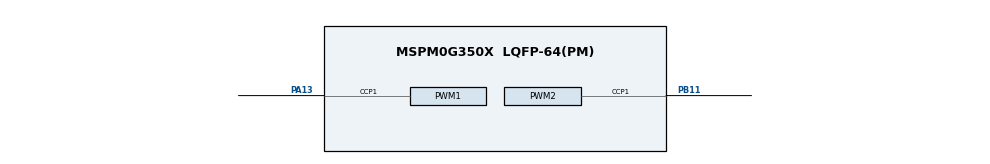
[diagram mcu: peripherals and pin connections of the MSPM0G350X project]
/**
 * @cliArgs --device "MSPM0G350X" --part "Default" --package "LQFP-64(PM)" --product "mspm0_sdk@2.05.00.05"
 * @versions {"tool":"1.24.0+4110"}
 */

/**
 * Import the modules used in this configuration.
 */
const GPIO   = scripting.addModule("/ti/driverlib/GPIO", {}, false);
const GPIO1  = GPIO.addInstance();
const GPIO2  = GPIO.addInstance();
const GPIO3  = GPIO.addInstance();
const GPIO4  = GPIO.addInstance();
const PWM    = scripting.addModule("/ti/driverlib/PWM", {}, false);
const PWM1   = PWM.addInstance();
const PWM2   = PWM.addInstance();
const SYSCTL = scripting.addModule("/ti/driverlib/SYSCTL");

/**
 * Write custom configuration values to the imported modules.
 */
GPIO1.$name                          = "GPIO_LEFT_MOTOR";
GPIO1.associatedPins.create(2);
GPIO1.associatedPins[0].$name        = "LEFT_PIN_0";
GPIO1.associatedPins[0].assignedPort = "PORTA";
GPIO1.associatedPins[0].assignedPin  = "28";
GPIO1.associatedPins[0].initialValue = "SET";
GPIO1.associatedPins[1].$name        = "LEFT_PIN_1";
GPIO1.associatedPins[1].initialValue = "SET";
GPIO1.associatedPins[1].assignedPort = "PORTA";
GPIO1.associatedPins[1].assignedPin  = "31";

const Board = scripting.addModule("/ti/driverlib/Board", {}, false);

GPIO2.$name                          = "GPIO_RIGHT_MOTOR";
GPIO2.associatedPins.create(2);
GPIO2.associatedPins[0].$name        = "RIGHT_PIN_0";
GPIO2.associatedPins[0].initialValue = "SET";
GPIO2.associatedPins[0].assignedPort = "PORTB";
GPIO2.associatedPins[0].assignedPin  = "13";
GPIO2.associatedPins[1].$name        = "RIGHT_PIN_1";
GPIO2.associatedPins[1].initialValue = "SET";
GPIO2.associatedPins[1].assignedPort = "PORTB";
GPIO2.associatedPins[1].assignedPin  = "20";

GPIO3.$name                          = "GPIO_SENSOR";
GPIO3.associatedPins.create(8);
GPIO3.associatedPins[0].$name        = "PIN_0";
GPIO3.associatedPins[0].direction    = "INPUT";
GPIO3.associatedPins[0].assignedPort = "PORTB";
GPIO3.associatedPins[0].assignedPin  = "3";
GPIO3.associatedPins[1].$name        = "PIN_1";
GPIO3.associatedPins[1].direction    = "INPUT";
GPIO3.associatedPins[1].assignedPort = "PORTB";
GPIO3.associatedPins[1].assignedPin  = "2";
GPIO3.associatedPins[2].$name        = "PIN_2";
GPIO3.associatedPins[2].direction    = "INPUT";
GPIO3.associatedPins[2].assignedPort = "PORTA";
GPIO3.associatedPins[2].assignedPin  = "27";
GPIO3.associatedPins[3].$name        = "PIN_3";
GPIO3.associatedPins[3].direction    = "INPUT";
GPIO3.associatedPins[3].assignedPort = "PORTB";
GPIO3.associatedPins[3].assignedPin  = "9";
GPIO3.associatedPins[4].$name        = "PIN_4";
GPIO3.associatedPins[4].direction    = "INPUT";
GPIO3.associatedPins[4].assignedPort = "PORTB";
GPIO3.associatedPins[4].assignedPin  = "24";
GPIO3.associatedPins[5].$name        = "PIN_5";
GPIO3.associatedPins[5].direction    = "INPUT";
GPIO3.associatedPins[5].assignedPort = "PORTA";
GPIO3.associatedPins[5].assignedPin  = "26";
GPIO3.associatedPins[6].$name        = "PIN_6";
GPIO3.associatedPins[6].direction    = "INPUT";
GPIO3.associatedPins[6].assignedPort = "PORTA";
GPIO3.associatedPins[6].assignedPin  = "8";
GPIO3.associatedPins[7].$name        = "PIN_7";
GPIO3.associatedPins[7].direction    = "INPUT";
GPIO3.associatedPins[7].assignedPort = "PORTA";
GPIO3.associatedPins[7].assignedPin  = "25";

GPIO4.$name                          = "GPIO_LED";
GPIO4.associatedPins[0].$name        = "PIN_LED";
GPIO4.associatedPins[0].assignedPort = "PORTA";
GPIO4.associatedPins[0].assignedPin  = "0";
GPIO4.associatedPins[0].initialValue = "SET";

PWM1.$name                      = "PWM_0";
PWM1.timerCount                 = 32000;
PWM1.ccIndex                    = [1];
PWM1.pwmMode                    = "EDGE_ALIGN_UP";
PWM1.ccp1PinConfig.$name        = "ti_driverlib_gpio_GPIOPinGeneric1";
PWM1.peripheral.$assign         = "TIMG0";
PWM1.peripheral.ccp1Pin.$assign = "PA13";
PWM1.PWM_CHANNEL_1.$name        = "ti_driverlib_pwm_PWMTimerCC0";
PWM1.PWM_CHANNEL_1.ccValue      = 9599;
PWM1.PWM_CHANNEL_1.dutyCycle    = 30;

PWM2.$name                      = "PWM_1";
PWM2.timerCount                 = 32000;
PWM2.ccIndex                    = [1];
PWM2.pwmMode                    = "EDGE_ALIGN_UP";
PWM2.ccp1PinConfig.$name        = "ti_driverlib_gpio_GPIOPinGeneric2";
PWM2.peripheral.$assign         = "TIMG6";
PWM2.peripheral.ccp1Pin.$assign = "PB11";
PWM2.PWM_CHANNEL_1.$name        = "ti_driverlib_pwm_PWMTimerCC1";
PWM2.PWM_CHANNEL_1.dutyCycle    = 30;

SYSCTL.forceDefaultClkConfig = true;

/**
 * Pinmux solution for unlocked pins/peripherals. This ensures that minor changes to the automatic solver in a future
 * version of the tool will not impact the pinmux you originally saw.  These lines can be completely deleted in order to
 * re-solve from scratch.
 */
GPIO1.associatedPins[0].pin.$suggestSolution = "PA28";
GPIO1.associatedPins[1].pin.$suggestSolution = "PA31";
Board.peripheral.$suggestSolution            = "DEBUGSS";
Board.peripheral.swclkPin.$suggestSolution   = "PA20";
Board.peripheral.swdioPin.$suggestSolution   = "PA19";
GPIO2.associatedPins[0].pin.$suggestSolution = "PB13";
GPIO2.associatedPins[1].pin.$suggestSolution = "PB20";
GPIO3.associatedPins[0].pin.$suggestSolution = "PB3";
GPIO3.associatedPins[1].pin.$suggestSolution = "PB2";
GPIO3.associatedPins[2].pin.$suggestSolution = "PA27";
GPIO3.associatedPins[3].pin.$suggestSolution = "PB9";
GPIO3.associatedPins[4].pin.$suggestSolution = "PB24";
GPIO3.associatedPins[5].pin.$suggestSolution = "PA26";
GPIO3.associatedPins[6].pin.$suggestSolution = "PA8";
GPIO3.associatedPins[7].pin.$suggestSolution = "PA25";
GPIO4.associatedPins[0].pin.$suggestSolution = "PA0";
SYSCTL.peripheral.$suggestSolution           = "SYSCTL";
